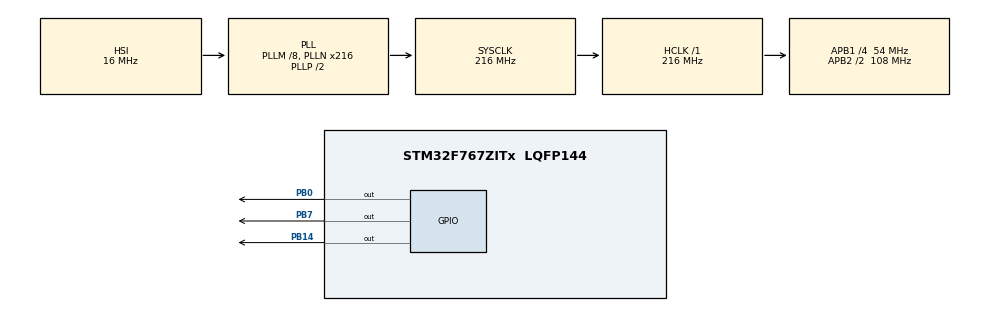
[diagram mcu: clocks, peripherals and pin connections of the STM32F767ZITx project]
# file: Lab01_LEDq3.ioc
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Mcu.Family=STM32F7
Mcu.Name=STM32F767ZITx
Mcu.Package=LQFP144
NVIC.PriorityGroup=NVIC_PRIORITYGROUP_4
PB0.Signal=GPIO_Output
PB14.Signal=GPIO_Output
PB7.Signal=GPIO_Output
ProjectManager.HeapSize=0x200
ProjectManager.StackSize=0x400
ProjectManager.TargetToolchain=MDK-ARM V5
RCC.AHBFreq_Value=216000000
RCC.APB1CLKDivider=RCC_HCLK_DIV4
RCC.APB1Freq_Value=54000000
RCC.APB1TimFreq_Value=108000000
RCC.APB2CLKDivider=RCC_HCLK_DIV2
RCC.APB2Freq_Value=108000000
RCC.APB2TimFreq_Value=216000000
RCC.CortexFreq_Value=216000000
RCC.HCLKFreq_Value=216000000
RCC.HSE_VALUE=25000000
RCC.HSI_VALUE=16000000
RCC.LSE_VALUE=32768
RCC.PLLM=8
RCC.PLLN=216
RCC.SYSCLKFreq_VALUE=216000000
RCC.SYSCLKSource=RCC_SYSCLKSOURCE_PLLCLK
RCC.USBFreq_Value=216000000
RCC.VCOOutputFreq_Value=432000000
board=custom

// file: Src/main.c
/* USER CODE BEGIN Header */
/**
  ******************************************************************************
  * @file           : main.c
  * @brief          : Main program body
  ******************************************************************************
  * @attention
  *
  * <h2><center>&copy; Copyright (c) 2019 STMicroelectronics.
  * All rights reserved.</center></h2>
  *
  * This software component is licensed by ST under BSD 3-Clause license,
  * the "License"; You may not use this file except in compliance with the
  * License. You may obtain a copy of the License at:
  *                        opensource.org/licenses/BSD-3-Clause
  *
  ******************************************************************************
  */
/* USER CODE END Header */

#include "main.h"
#include "gpio.h"

/* USER CODE BEGIN PV */
uint8_t num = 0;
/* USER CODE END PV */

void SystemClock_Config(void);
/* USER CODE BEGIN PFP */
void delay(uint32_t);
/* USER CODE END PFP */

int main(void)
{

  /* MCU Configuration--------------------------------------------------------*/

  /* Reset of all peripherals, Initializes the Flash interface and the Systick. */
  HAL_Init();

  /* Configure the system clock */
  SystemClock_Config();

  /* Initialize all configured peripherals */
  MX_GPIO_Init();
  /* USER CODE BEGIN 2 */
	//version4
	GPIOB->ODR = 0x00004081;
	num = 0;
  /* USER CODE END 2 */

  /* Infinite loop */
  while (1)
  {

    /* USER CODE BEGIN 3 */
		//version6
		//GPIOB->ODR= (GPIOB->ODR & 0xFFFFBFFF)|((num&4)<<12);
		//GPIOB->ODR= (GPIOB->ODR & 0xFFFFFF7F)|((num&2)<<6);
		//GPIOB->ODR= (GPIOB->ODR & 0xFFFFFFFE)|(num&1);
		//version5 logic error
		//GPIOB->ODR&=0xFFFFFFFF&((num&4)<<11);
		//GPIOB->ODR&=0xFFFFFFFF&((num&2)<<5);
		//GPIOB->ODR&=0xFFFFFFFF&(num&1);
		//version4
		if(num%4==0)
			GPIOB->ODR^=GPIO_PIN_14;
		if(num%2==0)
			GPIOB->ODR^=GPIO_PIN_7;
		GPIOB->ODR^=GPIO_PIN_0;

		delay(300);

		if(num >= 7)
			num=0;
		else
			num++;
		//test
		//GPIOB->ODR^=GPIO_PIN_0;
		//GPIOB->ODR^=GPIO_PIN_7;
		//GPIOB->ODR^=GPIO_PIN_14;
		//version3
		//GPIOB->ODR= (num%8>3);
		//GPIOB->ODR= (num%4>1);
		//GPIOB->ODR= (num%2==1);
		//version2
		//HAL_GPIO_WritePin(GPIOB, GPIO_PIN_14, num%8>3);
		//HAL_GPIO_WritePin(GPIOB, GPIO_PIN_7, num%4>1);
		//HAL_GPIO_WritePin(GPIOB, GPIO_PIN_0, num%2==1);
		//version1
		//if(num%8>3)
		//	HAL_GPIO_WritePin(GPIOB, GPIO_PIN_14, 1);
		//else
		//	HAL_GPIO_WritePin(GPIOB, GPIO_PIN_14, 0);
		//if(num%4>1)
		//	HAL_GPIO_WritePin(GPIOB, GPIO_PIN_7, 1);
		//else
		//	HAL_GPIO_WritePin(GPIOB, GPIO_PIN_7, 0);
		//if(num%2==1)
		//	HAL_GPIO_WritePin(GPIOB, GPIO_PIN_0, 1);
		//else
		//	HAL_GPIO_WritePin(GPIOB, GPIO_PIN_0, 0);

  }
  /* USER CODE END 3 */
}

void SystemClock_Config(void)
{
  RCC_OscInitTypeDef RCC_OscInitStruct = {0};
  RCC_ClkInitTypeDef RCC_ClkInitStruct = {0};

  /** Configure the main internal regulator output voltage
  */
  __HAL_RCC_PWR_CLK_ENABLE();
  __HAL_PWR_VOLTAGESCALING_CONFIG(PWR_REGULATOR_VOLTAGE_SCALE1);
  /** Initializes the CPU, AHB and APB busses clocks
  */
  RCC_OscInitStruct.OscillatorType = RCC_OSCILLATORTYPE_HSI;
  RCC_OscInitStruct.HSIState = RCC_HSI_ON;
  RCC_OscInitStruct.HSICalibrationValue = RCC_HSICALIBRATION_DEFAULT;
  RCC_OscInitStruct.PLL.PLLState = RCC_PLL_ON;
  RCC_OscInitStruct.PLL.PLLSource = RCC_PLLSOURCE_HSI;
  RCC_OscInitStruct.PLL.PLLM = 8;
  RCC_OscInitStruct.PLL.PLLN = 216;
  RCC_OscInitStruct.PLL.PLLP = RCC_PLLP_DIV2;
  RCC_OscInitStruct.PLL.PLLQ = 2;
  if (HAL_RCC_OscConfig(&RCC_OscInitStruct) != HAL_OK)
  {
    Error_Handler();
  }
  /** Activate the Over-Drive mode
  */
  if (HAL_PWREx_EnableOverDrive() != HAL_OK)
  {
    Error_Handler();
  }
  /** Initializes the CPU, AHB and APB busses clocks
  */
  RCC_ClkInitStruct.ClockType = RCC_CLOCKTYPE_HCLK|RCC_CLOCKTYPE_SYSCLK
                              |RCC_CLOCKTYPE_PCLK1|RCC_CLOCKTYPE_PCLK2;
  RCC_ClkInitStruct.SYSCLKSource = RCC_SYSCLKSOURCE_PLLCLK;
  RCC_ClkInitStruct.AHBCLKDivider = RCC_SYSCLK_DIV1;
  RCC_ClkInitStruct.APB1CLKDivider = RCC_HCLK_DIV4;
  RCC_ClkInitStruct.APB2CLKDivider = RCC_HCLK_DIV2;

  if (HAL_RCC_ClockConfig(&RCC_ClkInitStruct, FLASH_LATENCY_7) != HAL_OK)
  {
    Error_Handler();
  }
}

/* USER CODE BEGIN 4 */
	void delay(uint32_t ms)
	{
		volatile uint32_t i, j;

		for(i=0; i<ms; i++)
			for(j=0; j<27000; j++);
		return;
	}
/* USER CODE END 4 */

void Error_Handler(void)
{
}

/************************ (C) COPYRIGHT STMicroelectronics *****END OF FILE****/
